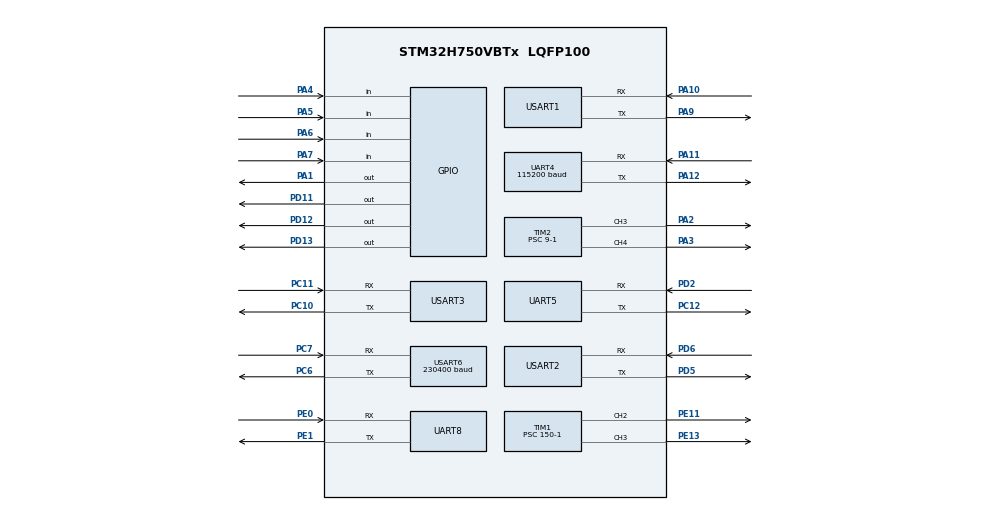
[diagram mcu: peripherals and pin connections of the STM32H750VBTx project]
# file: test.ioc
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CORTEX_M7.default_mode_Activation=1
Mcu.Family=STM32H7
Mcu.Name=STM32H750VBTx
Mcu.Package=LQFP100
NVIC.PriorityGroup=NVIC_PRIORITYGROUP_4
NVIC.UART4_IRQn=true\:0\:0\:false\:false\:true\:true\:true\:true
NVIC.UART5_IRQn=true\:0\:0\:false\:false\:true\:true\:true\:true
NVIC.UART8_IRQn=true\:0\:0\:false\:false\:true\:true\:true\:true
NVIC.USART1_IRQn=true\:0\:0\:false\:false\:true\:true\:true\:true
NVIC.USART2_IRQn=true\:0\:0\:false\:false\:true\:true\:true\:true
NVIC.USART3_IRQn=true\:0\:0\:false\:false\:true\:true\:true\:true
NVIC.USART6_IRQn=true\:0\:0\:false\:false\:true\:true\:true\:true
PA1.GPIO_ModeDefaultOutputPP=GPIO_MODE_OUTPUT_OD
PA1.GPIO_PuPd=GPIO_NOPULL
PA1.Signal=GPIO_Output
PA10.Mode=Asynchronous
PA10.Signal=USART1_RX
PA11.Mode=Asynchronous
PA11.Signal=UART4_RX
PA12.Mode=Asynchronous
PA12.Signal=UART4_TX
PA13\ (JTMS/SWDIO).Signal=DEBUG_JTMS-SWDIO
PA14\ (JTCK/SWCLK).Signal=DEBUG_JTCK-SWCLK
PA2.Signal=S_TIM2_CH3
PA3.Signal=S_TIM2_CH4
PA4.GPIO_PuPd=GPIO_NOPULL
PA4.Signal=GPIO_Input
PA5.GPIO_PuPd=GPIO_NOPULL
PA5.Signal=GPIO_Input
PA6.Signal=GPIO_Input
PA7.Signal=GPIO_Input
PA9.Mode=Asynchronous
PA9.Signal=USART1_TX
PC10.Mode=Asynchronous
PC10.Signal=USART3_TX
PC11.Mode=Asynchronous
PC11.Signal=USART3_RX
PC12.Mode=Asynchronous
PC12.Signal=UART5_TX
PC6.Mode=Asynchronous
PC6.Signal=USART6_TX
PC7.Mode=Asynchronous
PC7.Signal=USART6_RX
PD11.GPIO_ModeDefaultOutputPP=GPIO_MODE_OUTPUT_OD
PD11.GPIO_PuPd=GPIO_NOPULL
PD11.Signal=GPIO_Output
PD12.GPIO_ModeDefaultOutputPP=GPIO_MODE_OUTPUT_OD
PD12.GPIO_PuPd=GPIO_NOPULL
PD12.Signal=GPIO_Output
PD13.GPIO_ModeDefaultOutputPP=GPIO_MODE_OUTPUT_OD
PD13.GPIO_PuPd=GPIO_NOPULL
PD13.Signal=GPIO_Output
PD2.Mode=Asynchronous
PD2.Signal=UART5_RX
PD5.Mode=Asynchronous
PD5.Signal=USART2_TX
PD6.Mode=Asynchronous
PD6.Signal=USART2_RX
PE0.Mode=Asynchronous
PE0.Signal=UART8_RX
PE1.Mode=Asynchronous
PE1.Signal=UART8_TX
PE11.Signal=S_TIM1_CH2
PE13.Signal=S_TIM1_CH3
PH0-OSC_IN\ (PH0).Mode=HSE-External-Oscillator
PH0-OSC_IN\ (PH0).Signal=RCC_OSC_IN
PH1-OSC_OUT\ (PH1).Mode=HSE-External-Oscillator
PH1-OSC_OUT\ (PH1).Signal=RCC_OSC_OUT
ProjectManager.HeapSize=0x200
ProjectManager.StackSize=0x400
ProjectManager.TargetToolchain=MDK-ARM V5.32
RCC.ADCFreq_Value=50390625
RCC.APB1Freq_Value=37500000
RCC.APB2Freq_Value=37500000
RCC.APB3Freq_Value=37500000
RCC.APB4Freq_Value=37500000
RCC.CortexFreq_Value=75000000
RCC.D1PPRE=RCC_APB3_DIV2
RCC.D2PPRE1=RCC_APB1_DIV2
RCC.D2PPRE2=RCC_APB2_DIV2
RCC.D3PPRE=RCC_APB4_DIV2
RCC.DIVM1=2
RCC.DIVN1=12
RCC.HCLKFreq_Value=75000000
RCC.HSE_VALUE=25000000
RCC.PLL2FRACN=0
RCC.PLL3FRACN=0
RCC.PLLFRACN=0
RCC.PLLSourceVirtual=RCC_PLLSOURCE_HSE
RCC.SYSCLKFreq_VALUE=75000000
RCC.SYSCLKSource=RCC_SYSCLKSOURCE_PLLCLK
RCC.USBFreq_Value=75000000
SH.S_TIM1_CH2.0=TIM1_CH2,PWM Generation2 CH2
SH.S_TIM1_CH3.0=TIM1_CH3,PWM Generation3 CH3
SH.S_TIM2_CH3.0=TIM2_CH3,PWM Generation3 CH3
SH.S_TIM2_CH4.0=TIM2_CH4,PWM Generation4 CH4
TIM1.Channel-PWM\ Generation2\ CH2=TIM_CHANNEL_2
TIM1.Channel-PWM\ Generation3\ CH3=TIM_CHANNEL_3
TIM1.Period=10000-1
TIM1.Prescaler=150-1
TIM2.Channel-PWM\ Generation3\ CH3=TIM_CHANNEL_3
TIM2.Channel-PWM\ Generation4\ CH4=TIM_CHANNEL_4
TIM2.Period=1000-1
TIM2.Prescaler=9-1
UART4.BaudRate=115200
USART1.VirtualMode-Asynchronous=VM_ASYNC
USART2.VirtualMode-Asynchronous=VM_ASYNC
USART3.VirtualMode-Asynchronous=VM_ASYNC
USART6.BaudRate=230400
USART6.VirtualMode=VM_ASYNC
VP_MEMORYMAP_VS_MEMORYMAP.Mode=CurAppReg
VP_TIM1_VS_ClockSourceINT.Mode=Internal
VP_TIM2_VS_ClockSourceINT.Mode=Internal
board=custom

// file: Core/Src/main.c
/* USER CODE BEGIN Header */
/**
  ******************************************************************************
  * @file           : main.c
  * @brief          : Main program body
  ******************************************************************************
  * @attention
  *
  * Copyright (c) 2026 STMicroelectronics.
  * All rights reserved.
  *
  * This software is licensed under terms that can be found in the LICENSE file
  * in the root directory of this software component.
  * If no LICENSE file comes with this software, it is provided AS-IS.
  *
  ******************************************************************************
  */
/* USER CODE END Header */
#include "main.h"
#include "tim.h"
#include "usart.h"
#include "gpio.h"

/* USER CODE BEGIN Includes */
#include "common.h"
/* USER CODE END Includes */

void SystemClock_Config(void);
static void MPU_Config(void);

int main(void)
{

  /* MPU Configuration--------------------------------------------------------*/
  MPU_Config();

  /* MCU Configuration--------------------------------------------------------*/

  /* Reset of all peripherals, Initializes the Flash interface and the Systick. */
  HAL_Init();

  /* Configure the system clock */
  SystemClock_Config();

  /* Initialize all configured peripherals */
  MX_GPIO_Init();
  MX_USART1_UART_Init();
  MX_UART4_Init();
  MX_UART5_Init();
  MX_USART2_UART_Init();
  MX_USART3_UART_Init();
  MX_USART6_UART_Init();
  MX_TIM2_Init();
  MX_UART8_Init();
  MX_TIM1_Init();
  /* USER CODE BEGIN 2 */
  Init_Common(); // 初始化通用模块，包括 UART、电机、角度和 PID 控制器等
  /* USER CODE END 2 */

  /* Infinite loop */
  while (1)
  {

    /* USER CODE BEGIN 3 */
    main_task();
  }
  /* USER CODE END 3 */
}

void SystemClock_Config(void)
{
  RCC_OscInitTypeDef RCC_OscInitStruct = {0};
  RCC_ClkInitTypeDef RCC_ClkInitStruct = {0};

  /** Supply configuration update enable
  */
  HAL_PWREx_ConfigSupply(PWR_LDO_SUPPLY);

  /** Configure the main internal regulator output voltage
  */
  __HAL_PWR_VOLTAGESCALING_CONFIG(PWR_REGULATOR_VOLTAGE_SCALE3);

  while(!__HAL_PWR_GET_FLAG(PWR_FLAG_VOSRDY)) {}

  /** Initializes the RCC Oscillators according to the specified parameters
  * in the RCC_OscInitTypeDef structure.
  */
  RCC_OscInitStruct.OscillatorType = RCC_OSCILLATORTYPE_HSE;
  RCC_OscInitStruct.HSEState = RCC_HSE_ON;
  RCC_OscInitStruct.PLL.PLLState = RCC_PLL_ON;
  RCC_OscInitStruct.PLL.PLLSource = RCC_PLLSOURCE_HSE;
  RCC_OscInitStruct.PLL.PLLM = 2;
  RCC_OscInitStruct.PLL.PLLN = 12;
  RCC_OscInitStruct.PLL.PLLP = 2;
  RCC_OscInitStruct.PLL.PLLQ = 2;
  RCC_OscInitStruct.PLL.PLLR = 2;
  RCC_OscInitStruct.PLL.PLLRGE = RCC_PLL1VCIRANGE_3;
  RCC_OscInitStruct.PLL.PLLVCOSEL = RCC_PLL1VCOMEDIUM;
  RCC_OscInitStruct.PLL.PLLFRACN = 0;
  if (HAL_RCC_OscConfig(&RCC_OscInitStruct) != HAL_OK)
  {
    Error_Handler();
  }

  /** Initializes the CPU, AHB and APB buses clocks
  */
  RCC_ClkInitStruct.ClockType = RCC_CLOCKTYPE_HCLK|RCC_CLOCKTYPE_SYSCLK
                              |RCC_CLOCKTYPE_PCLK1|RCC_CLOCKTYPE_PCLK2
                              |RCC_CLOCKTYPE_D3PCLK1|RCC_CLOCKTYPE_D1PCLK1;
  RCC_ClkInitStruct.SYSCLKSource = RCC_SYSCLKSOURCE_PLLCLK;
  RCC_ClkInitStruct.SYSCLKDivider = RCC_SYSCLK_DIV1;
  RCC_ClkInitStruct.AHBCLKDivider = RCC_HCLK_DIV1;
  RCC_ClkInitStruct.APB3CLKDivider = RCC_APB3_DIV2;
  RCC_ClkInitStruct.APB1CLKDivider = RCC_APB1_DIV2;
  RCC_ClkInitStruct.APB2CLKDivider = RCC_APB2_DIV2;
  RCC_ClkInitStruct.APB4CLKDivider = RCC_APB4_DIV2;

  if (HAL_RCC_ClockConfig(&RCC_ClkInitStruct, FLASH_LATENCY_1) != HAL_OK)
  {
    Error_Handler();
  }
}

 /* MPU Configuration */

void MPU_Config(void)
{
  MPU_Region_InitTypeDef MPU_InitStruct = {0};

  /* Disables the MPU */
  HAL_MPU_Disable();

  /** Initializes and configures the Region and the memory to be protected
  */
  MPU_InitStruct.Enable = MPU_REGION_ENABLE;
  MPU_InitStruct.Number = MPU_REGION_NUMBER0;
  MPU_InitStruct.BaseAddress = 0x0;
  MPU_InitStruct.Size = MPU_REGION_SIZE_4GB;
  MPU_InitStruct.SubRegionDisable = 0x87;
  MPU_InitStruct.TypeExtField = MPU_TEX_LEVEL0;
  MPU_InitStruct.AccessPermission = MPU_REGION_NO_ACCESS;
  MPU_InitStruct.DisableExec = MPU_INSTRUCTION_ACCESS_DISABLE;
  MPU_InitStruct.IsShareable = MPU_ACCESS_SHAREABLE;
  MPU_InitStruct.IsCacheable = MPU_ACCESS_NOT_CACHEABLE;
  MPU_InitStruct.IsBufferable = MPU_ACCESS_NOT_BUFFERABLE;

  HAL_MPU_ConfigRegion(&MPU_InitStruct);
  /* Enables the MPU */
  HAL_MPU_Enable(MPU_PRIVILEGED_DEFAULT);

}

void Error_Handler(void)
{
  __disable_irq();
  while (1)
  {
  }
}
